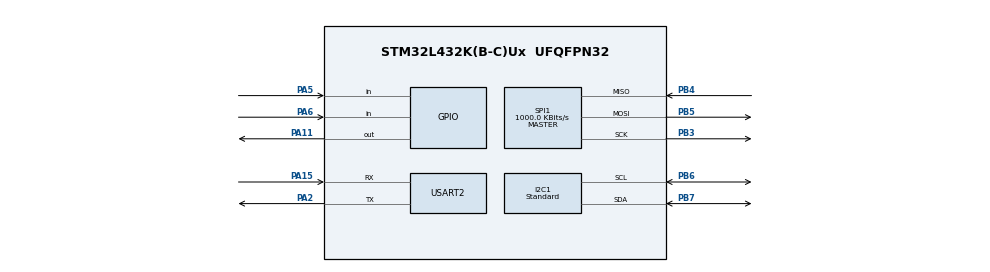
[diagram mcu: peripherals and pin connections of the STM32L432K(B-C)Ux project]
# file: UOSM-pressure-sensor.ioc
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FREERTOS.Tasks01=defaultTask,24,128,StartDefaultTask,Default,NULL,Dynamic,NULL,NULL
FREERTOS.configTOTAL_HEAP_SIZE=30000
FREERTOS.configUSE_NEWLIB_REENTRANT=1
I2C1.I2C_Speed_Mode=I2C_Standard
I2C1.NoStretchMode=I2C_NOSTRETCH_DISABLE
I2C1.Speed=50
I2C1.Timing=0x00000F3B
Mcu.Family=STM32L4
Mcu.Name=STM32L432K(B-C)Ux
Mcu.Package=UFQFPN32
NVIC.PriorityGroup=NVIC_PRIORITYGROUP_4
NVIC.TIM1_UP_TIM16_IRQn=true\:15\:0\:true\:false\:true\:false\:false\:true\:true
NVIC.TimeBase=TIM1_UP_TIM16_IRQn
NVIC.TimeBaseIP=TIM1
PA11.Signal=GPIO_Output
PA15\ (JTDI).Mode=Asynchronous
PA15\ (JTDI).Signal=USART2_RX
PA2.Mode=Asynchronous
PA2.Signal=USART2_TX
PA5.Signal=GPIO_Input
PA6.Signal=GPIO_Input
PB3\ (JTDO-TRACESWO).Mode=Full_Duplex_Master
PB3\ (JTDO-TRACESWO).Signal=SPI1_SCK
PB4\ (NJTRST).Mode=Full_Duplex_Master
PB4\ (NJTRST).Signal=SPI1_MISO
PB5.Mode=Full_Duplex_Master
PB5.Signal=SPI1_MOSI
PB6.Mode=I2C
PB6.Signal=I2C1_SCL
PB7.Mode=I2C
PB7.Signal=I2C1_SDA
ProjectManager.HeapSize=0x200
ProjectManager.StackSize=0x400
ProjectManager.TargetToolchain=STM32CubeIDE
RCC.HSE_VALUE=8000000
RCC.HSI48_VALUE=48000000
RCC.HSI_VALUE=16000000
RCC.LSE_VALUE=32768
RCC.MSI_VALUE=4000000
RCC.VCOOutputFreq_Value=32000000
SPI1.BaudRatePrescaler=SPI_BAUDRATEPRESCALER_4
SPI1.CLKPhase=SPI_PHASE_2EDGE
SPI1.CLKPolarity=SPI_POLARITY_HIGH
SPI1.CalculateBaudRate=1000.0 KBits/s
SPI1.DataSize=SPI_DATASIZE_8BIT
SPI1.Direction=SPI_DIRECTION_2LINES
SPI1.Mode=SPI_MODE_MASTER
SPI1.VirtualType=VM_MASTER
USART2.VirtualMode-Asynchronous=VM_ASYNC
VP_FREERTOS_VS_CMSIS_V2.Mode=CMSIS_V2
VP_SYS_VS_tim1.Mode=TIM1
board=custom

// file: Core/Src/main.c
/* USER CODE BEGIN Header */
/**
  ******************************************************************************
  * @file           : main.c
  * @brief          : Main program body
  ******************************************************************************
  * @attention
  *
  * Copyright (c) 2023 STMicroelectronics.
  * All rights reserved.
  *
  * This software is licensed under terms that can be found in the LICENSE file
  * in the root directory of this software component.
  * If no LICENSE file comes with this software, it is provided AS-IS.
  *
  ******************************************************************************
  */
/* USER CODE END Header */
#include "main.h"
#include "cmsis_os.h"

/* USER CODE BEGIN Includes */

#include "TaskManager.h"

/* USER CODE END Includes */

I2C_HandleTypeDef hi2c1;

SPI_HandleTypeDef hspi1;

UART_HandleTypeDef huart2;

/* Definitions for defaultTask */
osThreadId_t defaultTaskHandle;
const osThreadAttr_t defaultTask_attributes = {
  .name = "defaultTask",
  .stack_size = 128 * 4,
  .priority = (osPriority_t) osPriorityNormal,
};

void SystemClock_Config(void);
static void MX_GPIO_Init(void);
static void MX_I2C1_Init(void);
static void MX_SPI1_Init(void);
static void MX_USART2_UART_Init(void);
void StartDefaultTask(void *argument);

int main(void)
{

  /* MCU Configuration--------------------------------------------------------*/

  /* Reset of all peripherals, Initializes the Flash interface and the Systick. */
  HAL_Init();

  /* Configure the system clock */
  SystemClock_Config();

  /* Initialize all configured peripherals */
  MX_GPIO_Init();
  MX_I2C1_Init();
  MX_SPI1_Init();
  MX_USART2_UART_Init();

  /* Init scheduler */
  osKernelInitialize();

  /* Create the thread(s) */
  /* creation of defaultTask */
  defaultTaskHandle = osThreadNew(StartDefaultTask, NULL, &defaultTask_attributes);

  /* USER CODE BEGIN RTOS_THREADS */
  /* add threads, ... */

  RunTaskManager();

  /* USER CODE END RTOS_THREADS */

  /* Start scheduler */
  osKernelStart();

  /* We should never get here as control is now taken by the scheduler */

  /* Infinite loop */
  while (1)
  {

  }
}

void SystemClock_Config(void)
{
  RCC_OscInitTypeDef RCC_OscInitStruct = {0};
  RCC_ClkInitTypeDef RCC_ClkInitStruct = {0};

  /** Configure the main internal regulator output voltage
  */
  if (HAL_PWREx_ControlVoltageScaling(PWR_REGULATOR_VOLTAGE_SCALE1) != HAL_OK)
  {
    Error_Handler();
  }

  /** Initializes the RCC Oscillators according to the specified parameters
  * in the RCC_OscInitTypeDef structure.
  */
  RCC_OscInitStruct.OscillatorType = RCC_OSCILLATORTYPE_MSI;
  RCC_OscInitStruct.MSIState = RCC_MSI_ON;
  RCC_OscInitStruct.MSICalibrationValue = 0;
  RCC_OscInitStruct.MSIClockRange = RCC_MSIRANGE_6;
  RCC_OscInitStruct.PLL.PLLState = RCC_PLL_NONE;
  if (HAL_RCC_OscConfig(&RCC_OscInitStruct) != HAL_OK)
  {
    Error_Handler();
  }

  /** Initializes the CPU, AHB and APB buses clocks
  */
  RCC_ClkInitStruct.ClockType = RCC_CLOCKTYPE_HCLK|RCC_CLOCKTYPE_SYSCLK
                              |RCC_CLOCKTYPE_PCLK1|RCC_CLOCKTYPE_PCLK2;
  RCC_ClkInitStruct.SYSCLKSource = RCC_SYSCLKSOURCE_MSI;
  RCC_ClkInitStruct.AHBCLKDivider = RCC_SYSCLK_DIV1;
  RCC_ClkInitStruct.APB1CLKDivider = RCC_HCLK_DIV1;
  RCC_ClkInitStruct.APB2CLKDivider = RCC_HCLK_DIV1;

  if (HAL_RCC_ClockConfig(&RCC_ClkInitStruct, FLASH_LATENCY_0) != HAL_OK)
  {
    Error_Handler();
  }
}

static void MX_I2C1_Init(void)
{

  hi2c1.Instance = I2C1;
  hi2c1.Init.Timing = 0x00000F3B;
  hi2c1.Init.OwnAddress1 = 0;
  hi2c1.Init.AddressingMode = I2C_ADDRESSINGMODE_7BIT;
  hi2c1.Init.DualAddressMode = I2C_DUALADDRESS_DISABLE;
  hi2c1.Init.OwnAddress2 = 0;
  hi2c1.Init.OwnAddress2Masks = I2C_OA2_NOMASK;
  hi2c1.Init.GeneralCallMode = I2C_GENERALCALL_DISABLE;
  hi2c1.Init.NoStretchMode = I2C_NOSTRETCH_DISABLE;
  if (HAL_I2C_Init(&hi2c1) != HAL_OK)
  {
    Error_Handler();
  }

  /** Configure Analogue filter
  */
  if (HAL_I2CEx_ConfigAnalogFilter(&hi2c1, I2C_ANALOGFILTER_ENABLE) != HAL_OK)
  {
    Error_Handler();
  }

  /** Configure Digital filter
  */
  if (HAL_I2CEx_ConfigDigitalFilter(&hi2c1, 0) != HAL_OK)
  {
    Error_Handler();
  }

}

static void MX_SPI1_Init(void)
{

  /* SPI1 parameter configuration*/
  hspi1.Instance = SPI1;
  hspi1.Init.Mode = SPI_MODE_MASTER;
  hspi1.Init.Direction = SPI_DIRECTION_2LINES;
  hspi1.Init.DataSize = SPI_DATASIZE_8BIT;
  hspi1.Init.CLKPolarity = SPI_POLARITY_HIGH;
  hspi1.Init.CLKPhase = SPI_PHASE_2EDGE;
  hspi1.Init.NSS = SPI_NSS_SOFT;
  hspi1.Init.BaudRatePrescaler = SPI_BAUDRATEPRESCALER_4;
  hspi1.Init.FirstBit = SPI_FIRSTBIT_MSB;
  hspi1.Init.TIMode = SPI_TIMODE_DISABLE;
  hspi1.Init.CRCCalculation = SPI_CRCCALCULATION_DISABLE;
  hspi1.Init.CRCPolynomial = 7;
  hspi1.Init.CRCLength = SPI_CRC_LENGTH_DATASIZE;
  hspi1.Init.NSSPMode = SPI_NSS_PULSE_DISABLE;
  if (HAL_SPI_Init(&hspi1) != HAL_OK)
  {
    Error_Handler();
  }

}

static void MX_USART2_UART_Init(void)
{

  huart2.Instance = USART2;
  huart2.Init.BaudRate = 115200;
  huart2.Init.WordLength = UART_WORDLENGTH_8B;
  huart2.Init.StopBits = UART_STOPBITS_1;
  huart2.Init.Parity = UART_PARITY_NONE;
  huart2.Init.Mode = UART_MODE_TX_RX;
  huart2.Init.HwFlowCtl = UART_HWCONTROL_NONE;
  huart2.Init.OverSampling = UART_OVERSAMPLING_16;
  huart2.Init.OneBitSampling = UART_ONE_BIT_SAMPLE_DISABLE;
  huart2.AdvancedInit.AdvFeatureInit = UART_ADVFEATURE_NO_INIT;
  if (HAL_UART_Init(&huart2) != HAL_OK)
  {
    Error_Handler();
  }

}

static void MX_GPIO_Init(void)
{
  GPIO_InitTypeDef GPIO_InitStruct = {0};

  /* GPIO Ports Clock Enable */
  __HAL_RCC_GPIOA_CLK_ENABLE();
  __HAL_RCC_GPIOB_CLK_ENABLE();

  /*Configure GPIO pin Output Level */
  HAL_GPIO_WritePin(GPIOA, GPIO_PIN_11, GPIO_PIN_RESET);

  /*Configure GPIO pins : PA5 PA6 */
  GPIO_InitStruct.Pin = GPIO_PIN_5|GPIO_PIN_6;
  GPIO_InitStruct.Mode = GPIO_MODE_INPUT;
  GPIO_InitStruct.Pull = GPIO_NOPULL;
  HAL_GPIO_Init(GPIOA, &GPIO_InitStruct);

  /*Configure GPIO pin : PA11 */
  GPIO_InitStruct.Pin = GPIO_PIN_11;
  GPIO_InitStruct.Mode = GPIO_MODE_OUTPUT_PP;
  GPIO_InitStruct.Pull = GPIO_NOPULL;
  GPIO_InitStruct.Speed = GPIO_SPEED_FREQ_LOW;
  HAL_GPIO_Init(GPIOA, &GPIO_InitStruct);

}

void StartDefaultTask(void *argument)
{
  for(;;)
  {
    osDelay(1);
  }
}

void HAL_TIM_PeriodElapsedCallback(TIM_HandleTypeDef *htim)
{
  if (htim->Instance == TIM1) {
    HAL_IncTick();
  }
}

void Error_Handler(void)
{
  __disable_irq();
  while (1)
  {
  }
}
